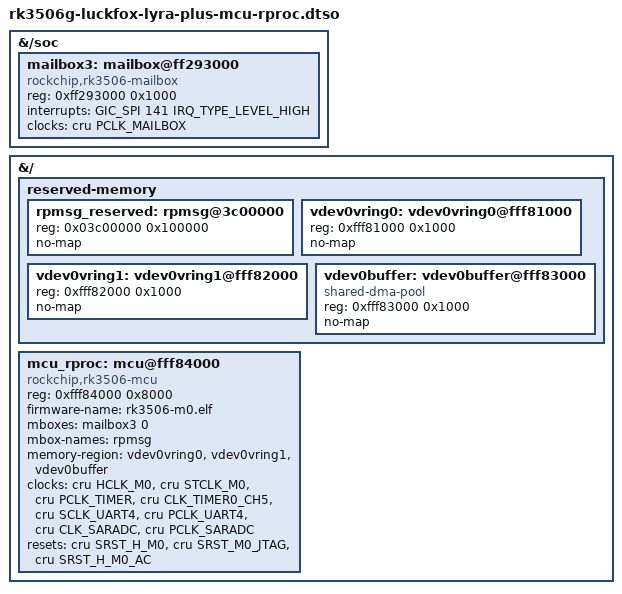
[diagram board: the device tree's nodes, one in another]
// SPDX-License-Identifier: (GPL-2.0+ OR MIT)
/*
 * Luckfox Lyra Plus M0 remoteproc overlay
 *
 * Adds the RK3506 M0 core (remoteproc), its mailbox, the shared RPMsg
 * memory carve-outs and the M0 firmware reserved region.
 *
 */

/dts-v1/;
/plugin/;

#include <dt-bindings/clock/rockchip,rk3506-cru.h>
#include <dt-bindings/reset/rockchip,rk3506-cru.h>
#include <dt-bindings/interrupt-controller/arm-gic.h>

&{/soc} {
	mailbox3: mailbox@ff293000 {
		compatible = "rockchip,rk3506-mailbox";
		reg = <0xff293000 0x1000>;
		interrupts = <GIC_SPI 141 IRQ_TYPE_LEVEL_HIGH>;
		clocks = <&cru PCLK_MAILBOX>;
		#mbox-cells = <1>;
		status = "okay";
	};
};

&{/} {
	reserved-memory {
		#address-cells = <1>;
		#size-cells = <1>;
		ranges;

		rpmsg_reserved: rpmsg@3c00000 {
			reg = <0x03c00000 0x100000>;
			no-map;
		};

		vdev0vring0: vdev0vring0@fff81000 {
			reg = <0xfff81000 0x1000>;
			no-map;
		};

		vdev0vring1: vdev0vring1@fff82000 {
			reg = <0xfff82000 0x1000>;
			no-map;
		};

		vdev0buffer: vdev0buffer@fff83000 {
			compatible = "shared-dma-pool";
			reg = <0xfff83000 0x1000>;
			no-map;
		};
	};

	mcu_rproc: mcu@fff84000 {
		compatible = "rockchip,rk3506-mcu";
		reg = <0xfff84000 0x8000>;
		firmware-name = "rk3506-m0.elf";
		mboxes = <&mailbox3 0>;
		mbox-names = "rpmsg";
		memory-region = <&vdev0vring0>, <&vdev0vring1>, <&vdev0buffer>;
		clocks = <&cru HCLK_M0>, <&cru STCLK_M0>,
			 <&cru PCLK_TIMER>, <&cru CLK_TIMER0_CH5>,
			 <&cru SCLK_UART4>, <&cru PCLK_UART4>,
			 <&cru CLK_SARADC>, <&cru PCLK_SARADC>;
		resets = <&cru SRST_H_M0>, <&cru SRST_M0_JTAG>, <&cru SRST_H_M0_AC>;
		reset-names = "h_m0", "m0_jtag", "hresetn_m0_ac";
	};
};
